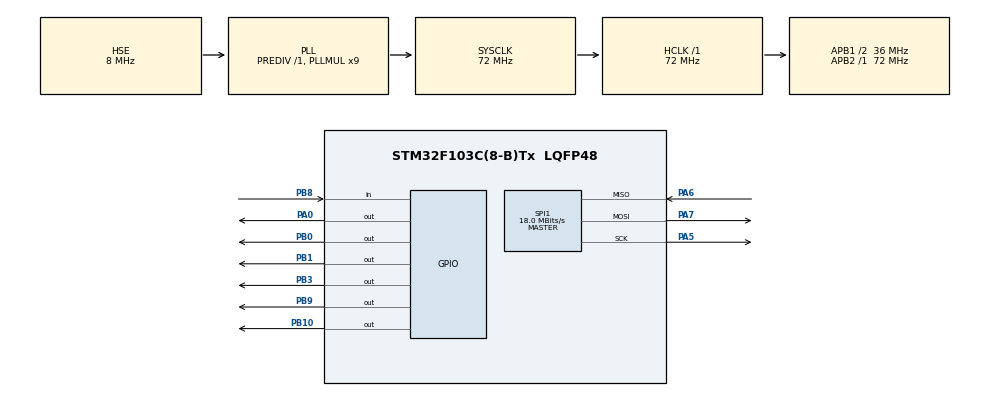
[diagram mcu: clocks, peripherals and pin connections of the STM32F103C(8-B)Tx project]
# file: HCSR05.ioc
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Mcu.Family=STM32F1
Mcu.Name=STM32F103C(8-B)Tx
Mcu.Package=LQFP48
NVIC.PriorityGroup=NVIC_PRIORITYGROUP_4
PA0-WKUP.Signal=GPIO_Output
PA13.Mode=Serial_Wire
PA13.Signal=SYS_JTMS-SWDIO
PA14.Mode=Serial_Wire
PA14.Signal=SYS_JTCK-SWCLK
PA5.Mode=Full_Duplex_Master
PA5.Signal=SPI1_SCK
PA6.Mode=Full_Duplex_Master
PA6.Signal=SPI1_MISO
PA7.Mode=Full_Duplex_Master
PA7.Signal=SPI1_MOSI
PB0.Signal=GPIO_Output
PB1.Signal=GPIO_Output
PB10.Signal=GPIO_Output
PB3.Signal=GPIO_Output
PB8.Signal=GPIO_Input
PB9.Signal=GPIO_Output
PD0-OSC_IN.Mode=HSE-External-Oscillator
PD0-OSC_IN.Signal=RCC_OSC_IN
PD1-OSC_OUT.Mode=HSE-External-Oscillator
PD1-OSC_OUT.Signal=RCC_OSC_OUT
ProjectManager.HeapSize=0x200
ProjectManager.StackSize=0x400
ProjectManager.TargetToolchain=MDK-ARM V5.32
RCC.AHBFreq_Value=72000000
RCC.APB1CLKDivider=RCC_HCLK_DIV2
RCC.APB1Freq_Value=36000000
RCC.APB1TimFreq_Value=72000000
RCC.APB2Freq_Value=72000000
RCC.APB2TimFreq_Value=72000000
RCC.HCLKFreq_Value=72000000
RCC.PLLMUL=RCC_PLL_MUL9
RCC.PLLSourceVirtual=RCC_PLLSOURCE_HSE
RCC.SYSCLKFreq_VALUE=72000000
RCC.SYSCLKSource=RCC_SYSCLKSOURCE_PLLCLK
RCC.USBFreq_Value=72000000
SPI1.BaudRatePrescaler=SPI_BAUDRATEPRESCALER_4
SPI1.CalculateBaudRate=18.0 MBits/s
SPI1.Direction=SPI_DIRECTION_2LINES
SPI1.Mode=SPI_MODE_MASTER
SPI1.VirtualType=VM_MASTER
TIM2.Prescaler=71
VP_TIM2_VS_ClockSourceINT.Mode=Internal
board=custom

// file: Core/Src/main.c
/* USER CODE BEGIN Header */
/**
  ******************************************************************************
  * @file           : main.c
  * @brief          : Main program body
  ******************************************************************************
  * @attention
  *
  * Copyright (c) 2026 STMicroelectronics.
  * All rights reserved.
  *
  * This software is licensed under terms that can be found in the LICENSE file
  * in the root directory of this software component.
  * If no LICENSE file comes with this software, it is provided AS-IS.
  *
  ******************************************************************************
  */
/* USER CODE END Header */
#include "main.h"

/* USER CODE BEGIN Includes */
	#include "TFT.h"
	#include "HCSR05.h"
/* USER CODE END Includes */

SPI_HandleTypeDef hspi1;

TIM_HandleTypeDef htim2;

void SystemClock_Config(void);
static void MX_GPIO_Init(void);
static void MX_SPI1_Init(void);
static void MX_TIM2_Init(void);

/* USER CODE BEGIN 0 */
float distance = 0;
uint8_t posX = 0;

/* USER CODE END 0 */

int main(void)
{

  /* MCU Configuration--------------------------------------------------------*/

  /* Reset of all peripherals, Initializes the Flash interface and the Systick. */
  HAL_Init();

  /* Configure the system clock */
  SystemClock_Config();

  /* Initialize all configured peripherals */
  MX_GPIO_Init();
  MX_SPI1_Init();
  MX_TIM2_Init();
  /* USER CODE BEGIN 2 */
	SR05_Init();
	initTFT();
	drawMap();
  /* USER CODE END 2 */

  /* Infinite loop */
  while (1)
  {

    /* USER CODE BEGIN 3 */
		distance = SR05_GetDis(); // <= 10
		posX = 10 + (distance*10.5);
		drawBlinkingPoint(posX, 80);
		HAL_Delay(100);

  }
  /* USER CODE END 3 */
}

void SystemClock_Config(void)
{
  RCC_OscInitTypeDef RCC_OscInitStruct = {0};
  RCC_ClkInitTypeDef RCC_ClkInitStruct = {0};

  /** Initializes the RCC Oscillators according to the specified parameters
  * in the RCC_OscInitTypeDef structure.
  */
  RCC_OscInitStruct.OscillatorType = RCC_OSCILLATORTYPE_HSE;
  RCC_OscInitStruct.HSEState = RCC_HSE_ON;
  RCC_OscInitStruct.HSEPredivValue = RCC_HSE_PREDIV_DIV1;
  RCC_OscInitStruct.HSIState = RCC_HSI_ON;
  RCC_OscInitStruct.PLL.PLLState = RCC_PLL_ON;
  RCC_OscInitStruct.PLL.PLLSource = RCC_PLLSOURCE_HSE;
  RCC_OscInitStruct.PLL.PLLMUL = RCC_PLL_MUL9;
  if (HAL_RCC_OscConfig(&RCC_OscInitStruct) != HAL_OK)
  {
    Error_Handler();
  }

  /** Initializes the CPU, AHB and APB buses clocks
  */
  RCC_ClkInitStruct.ClockType = RCC_CLOCKTYPE_HCLK|RCC_CLOCKTYPE_SYSCLK
                              |RCC_CLOCKTYPE_PCLK1|RCC_CLOCKTYPE_PCLK2;
  RCC_ClkInitStruct.SYSCLKSource = RCC_SYSCLKSOURCE_PLLCLK;
  RCC_ClkInitStruct.AHBCLKDivider = RCC_SYSCLK_DIV1;
  RCC_ClkInitStruct.APB1CLKDivider = RCC_HCLK_DIV2;
  RCC_ClkInitStruct.APB2CLKDivider = RCC_HCLK_DIV1;

  if (HAL_RCC_ClockConfig(&RCC_ClkInitStruct, FLASH_LATENCY_2) != HAL_OK)
  {
    Error_Handler();
  }
}

static void MX_SPI1_Init(void)
{

  /* SPI1 parameter configuration*/
  hspi1.Instance = SPI1;
  hspi1.Init.Mode = SPI_MODE_MASTER;
  hspi1.Init.Direction = SPI_DIRECTION_2LINES;
  hspi1.Init.DataSize = SPI_DATASIZE_8BIT;
  hspi1.Init.CLKPolarity = SPI_POLARITY_LOW;
  hspi1.Init.CLKPhase = SPI_PHASE_1EDGE;
  hspi1.Init.NSS = SPI_NSS_SOFT;
  hspi1.Init.BaudRatePrescaler = SPI_BAUDRATEPRESCALER_4;
  hspi1.Init.FirstBit = SPI_FIRSTBIT_MSB;
  hspi1.Init.TIMode = SPI_TIMODE_DISABLE;
  hspi1.Init.CRCCalculation = SPI_CRCCALCULATION_DISABLE;
  hspi1.Init.CRCPolynomial = 10;
  if (HAL_SPI_Init(&hspi1) != HAL_OK)
  {
    Error_Handler();
  }

}

static void MX_TIM2_Init(void)
{

  TIM_ClockConfigTypeDef sClockSourceConfig = {0};
  TIM_MasterConfigTypeDef sMasterConfig = {0};

  htim2.Instance = TIM2;
  htim2.Init.Prescaler = 71;
  htim2.Init.CounterMode = TIM_COUNTERMODE_UP;
  htim2.Init.Period = 65535;
  htim2.Init.ClockDivision = TIM_CLOCKDIVISION_DIV1;
  htim2.Init.AutoReloadPreload = TIM_AUTORELOAD_PRELOAD_DISABLE;
  if (HAL_TIM_Base_Init(&htim2) != HAL_OK)
  {
    Error_Handler();
  }
  sClockSourceConfig.ClockSource = TIM_CLOCKSOURCE_INTERNAL;
  if (HAL_TIM_ConfigClockSource(&htim2, &sClockSourceConfig) != HAL_OK)
  {
    Error_Handler();
  }
  sMasterConfig.MasterOutputTrigger = TIM_TRGO_RESET;
  sMasterConfig.MasterSlaveMode = TIM_MASTERSLAVEMODE_DISABLE;
  if (HAL_TIMEx_MasterConfigSynchronization(&htim2, &sMasterConfig) != HAL_OK)
  {
    Error_Handler();
  }

}

static void MX_GPIO_Init(void)
{
  GPIO_InitTypeDef GPIO_InitStruct = {0};

  /* GPIO Ports Clock Enable */
  __HAL_RCC_GPIOD_CLK_ENABLE();
  __HAL_RCC_GPIOA_CLK_ENABLE();
  __HAL_RCC_GPIOB_CLK_ENABLE();

  /*Configure GPIO pin Output Level */
  HAL_GPIO_WritePin(GPIOA, GPIO_PIN_0, GPIO_PIN_RESET);

  /*Configure GPIO pin Output Level */
  HAL_GPIO_WritePin(GPIOB, GPIO_PIN_0|GPIO_PIN_1|GPIO_PIN_10|GPIO_PIN_3
                          |GPIO_PIN_9, GPIO_PIN_RESET);

  /*Configure GPIO pin : PA0 */
  GPIO_InitStruct.Pin = GPIO_PIN_0;
  GPIO_InitStruct.Mode = GPIO_MODE_OUTPUT_PP;
  GPIO_InitStruct.Pull = GPIO_NOPULL;
  GPIO_InitStruct.Speed = GPIO_SPEED_FREQ_LOW;
  HAL_GPIO_Init(GPIOA, &GPIO_InitStruct);

  /*Configure GPIO pins : PB0 PB1 PB10 PB3
                           PB9 */
  GPIO_InitStruct.Pin = GPIO_PIN_0|GPIO_PIN_1|GPIO_PIN_10|GPIO_PIN_3
                          |GPIO_PIN_9;
  GPIO_InitStruct.Mode = GPIO_MODE_OUTPUT_PP;
  GPIO_InitStruct.Pull = GPIO_NOPULL;
  GPIO_InitStruct.Speed = GPIO_SPEED_FREQ_LOW;
  HAL_GPIO_Init(GPIOB, &GPIO_InitStruct);

  /*Configure GPIO pin : PB8 */
  GPIO_InitStruct.Pin = GPIO_PIN_8;
  GPIO_InitStruct.Mode = GPIO_MODE_INPUT;
  GPIO_InitStruct.Pull = GPIO_NOPULL;
  HAL_GPIO_Init(GPIOB, &GPIO_InitStruct);

}

void Error_Handler(void)
{
  __disable_irq();
  while (1)
  {
  }
}
